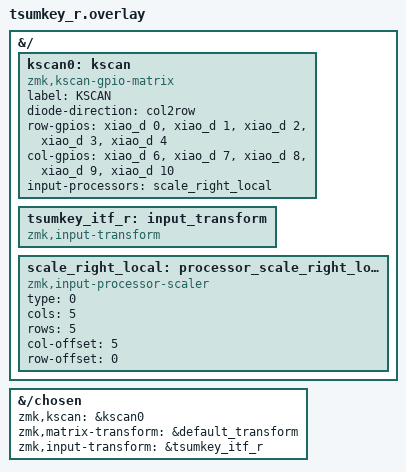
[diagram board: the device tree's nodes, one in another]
/* tsumkey_r.overlay（右：Central） */
#include "tsumkey.dtsi"
#include <input/processors.dtsi>

/* 右の物理スキャン */
&{/} {
    kscan0: kscan {
        compatible = "zmk,kscan-gpio-matrix";
        label = "KSCAN";
        diode-direction = "col2row";
        row-gpios = <&xiao_d 0 (GPIO_ACTIVE_HIGH | GPIO_PULL_DOWN)>,
                    <&xiao_d 1 (GPIO_ACTIVE_HIGH | GPIO_PULL_DOWN)>,
                    <&xiao_d 2 (GPIO_ACTIVE_HIGH | GPIO_PULL_DOWN)>,
                    <&xiao_d 3 (GPIO_ACTIVE_HIGH | GPIO_PULL_DOWN)>,
                    <&xiao_d 4 (GPIO_ACTIVE_HIGH | GPIO_PULL_DOWN)>;
        col-gpios = <&xiao_d 6 GPIO_ACTIVE_HIGH>,
                    <&xiao_d 7 GPIO_ACTIVE_HIGH>,
                    <&xiao_d 8 GPIO_ACTIVE_HIGH>,
                    <&xiao_d 9 GPIO_ACTIVE_HIGH>,
                    <&xiao_d 10 GPIO_ACTIVE_HIGH>;
    };
};

&{/chosen} {
    zmk,kscan = &kscan0;
    zmk,matrix-transform = &default_transform;   /* 共通 10×5 を採用 */
    zmk,input-transform = &tsumkey_itf_r;        /* 右だけ入力チェーンを使う */
};

/* 入力チェーン定義（中身は空でOK） */
&{/} {
    tsumkey_itf_r: input_transform {
        compatible = "zmk,input-transform";
    };

    /* 右ローカル用スケーラ（+5列） */
    scale_right_local: processor_scale_right_local {
        compatible = "zmk,input-processor-scaler";

        /* 型: matrix (=0) / セル数: 2 固定 */
        type = <0>;
        #input-processor-cells = <2>;

        /* ★ “簡易版” 推奨：これが一番コケにくい */
        cols = <5>;
        rows = <5>;
        col-offset = <5>;
        row-offset = <0>;
    };
};

/* 右ローカル入力にだけスケーラを適用 */
&kscan0 {
    input-processors = <&scale_right_local>;
};
